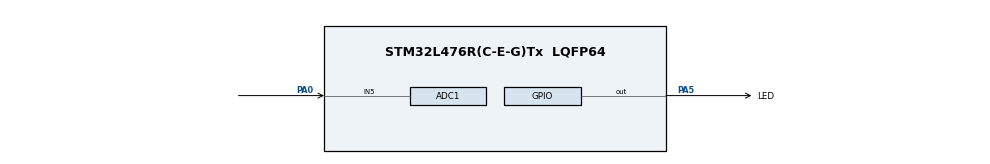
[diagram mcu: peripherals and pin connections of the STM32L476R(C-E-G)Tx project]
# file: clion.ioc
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ADC1.Channel-0\#ChannelRegularConversion=ADC_CHANNEL_5
ADC1.ClockPrescaler=ADC_CLOCK_SYNC_PCLK_DIV4
ADC1.NbrOfConversionFlag=1
ADC1.OffsetNumber-0\#ChannelRegularConversion=ADC_OFFSET_NONE
ADC1.Rank-0\#ChannelRegularConversion=1
ADC1.SamplingTime-0\#ChannelRegularConversion=ADC_SAMPLETIME_92CYCLES_5
ADC1.master=1
Mcu.Family=STM32L4
Mcu.Name=STM32L476R(C-E-G)Tx
Mcu.Package=LQFP64
NVIC.ADC1_2_IRQn=true\:0\:0\:false\:false\:true\:true\:true
NVIC.PriorityGroup=NVIC_PRIORITYGROUP_4
PA0.Signal=ADCx_IN5
PA5.GPIO_Label=LED
PA5.Signal=GPIO_Output
ProjectManager.HeapSize=0x200
ProjectManager.StackSize=0x400
ProjectManager.TargetToolchain=SW4STM32
RCC.ADCFreq_Value=32000000
RCC.HSE_VALUE=8000000
RCC.HSI_VALUE=16000000
RCC.LSE_VALUE=32768
RCC.MSI_VALUE=4000000
RCC.PLLSAI1N=16
RCC.USBFreq_Value=32000000
RCC.VCOOutputFreq_Value=32000000
SH.ADCx_IN5.0=ADC1_IN5,IN5-Single-Ended
board=custom

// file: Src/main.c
/* USER CODE BEGIN Header */
/**
 ******************************************************************************
 * @file           : main.c
 * @brief          : Main program body
 ******************************************************************************
 * @attention
 *
 * <h2><center>&copy; Copyright (c) 2019 STMicroelectronics.
 * All rights reserved.</center></h2>
 *
 * This software component is licensed by ST under BSD 3-Clause license,
 * the "License"; You may not use this file except in compliance with the
 * License. You may obtain a copy of the License at:
 *                        opensource.org/licenses/BSD-3-Clause
 *
 ******************************************************************************
 */
/* USER CODE END Header */

#include "main.h"

ADC_HandleTypeDef hadc1;

void SystemClock_Config(void);
static void MX_GPIO_Init(void);
static void MX_ADC1_Init(void);

/* USER CODE BEGIN 0 */
uint32_t value;

void HAL_ADC_ConvCpltCallback(ADC_HandleTypeDef *hadc1) {
    value = HAL_ADC_GetValue(hadc1);
    HAL_ADC_Start_IT(hadc1); // Re-Start ADC1 under Interrupt
    // this is necessary because we don'use
    // the Continuous Conversion Mode
}
/* USER CODE END 0 */

int main(void)
{

  /* MCU Configuration--------------------------------------------------------*/

  /* Reset of all peripherals, Initializes the Flash interface and the Systick. */
  HAL_Init();

  /* Configure the system clock */
  SystemClock_Config();

  /* Initialize all configured peripherals */
  MX_GPIO_Init();
  MX_ADC1_Init();
  /* USER CODE BEGIN 2 */
    HAL_ADC_Start_IT(&hadc1);  // start ADC in interrupt mode
  /* USER CODE END 2 */

  /* Infinite loop */
  /* USER CODE BEGIN WHILE */
    while (1) {
        HAL_GPIO_TogglePin(LED_GPIO_Port, LED_Pin);
        HAL_Delay(value / 10 + 20);
//        TODO implement storage to flash
        if (value > 9999) {
            break;
        }
    /* USER CODE END WHILE */

    }
}

void SystemClock_Config(void)
{
  RCC_OscInitTypeDef RCC_OscInitStruct = {0};
  RCC_ClkInitTypeDef RCC_ClkInitStruct = {0};

  /** Initializes the CPU, AHB and APB busses clocks
  */
  RCC_OscInitStruct.OscillatorType = RCC_OSCILLATORTYPE_MSI;
  RCC_OscInitStruct.MSIState = RCC_MSI_ON;
  RCC_OscInitStruct.MSICalibrationValue = 0;
  RCC_OscInitStruct.MSIClockRange = RCC_MSIRANGE_6;
  RCC_OscInitStruct.PLL.PLLState = RCC_PLL_NONE;
  if (HAL_RCC_OscConfig(&RCC_OscInitStruct) != HAL_OK)
  {
    Error_Handler();
  }
  /** Initializes the CPU, AHB and APB busses clocks
  */
  RCC_ClkInitStruct.ClockType = RCC_CLOCKTYPE_HCLK|RCC_CLOCKTYPE_SYSCLK
                              |RCC_CLOCKTYPE_PCLK1|RCC_CLOCKTYPE_PCLK2;
  RCC_ClkInitStruct.SYSCLKSource = RCC_SYSCLKSOURCE_MSI;
  RCC_ClkInitStruct.AHBCLKDivider = RCC_SYSCLK_DIV1;
  RCC_ClkInitStruct.APB1CLKDivider = RCC_HCLK_DIV1;
  RCC_ClkInitStruct.APB2CLKDivider = RCC_HCLK_DIV1;

  if (HAL_RCC_ClockConfig(&RCC_ClkInitStruct, FLASH_LATENCY_0) != HAL_OK)
  {
    Error_Handler();
  }
  /** Configure the main internal regulator output voltage
  */
  if (HAL_PWREx_ControlVoltageScaling(PWR_REGULATOR_VOLTAGE_SCALE1) != HAL_OK)
  {
    Error_Handler();
  }
}

static void MX_ADC1_Init(void)
{

  ADC_MultiModeTypeDef multimode = {0};
  ADC_ChannelConfTypeDef sConfig = {0};

  /** Common config
  */
  hadc1.Instance = ADC1;
  hadc1.Init.ClockPrescaler = ADC_CLOCK_SYNC_PCLK_DIV4;
  hadc1.Init.Resolution = ADC_RESOLUTION_12B;
  hadc1.Init.DataAlign = ADC_DATAALIGN_RIGHT;
  hadc1.Init.ScanConvMode = ADC_SCAN_DISABLE;
  hadc1.Init.EOCSelection = ADC_EOC_SINGLE_CONV;
  hadc1.Init.LowPowerAutoWait = DISABLE;
  hadc1.Init.ContinuousConvMode = DISABLE;
  hadc1.Init.NbrOfConversion = 1;
  hadc1.Init.DiscontinuousConvMode = DISABLE;
  hadc1.Init.ExternalTrigConv = ADC_SOFTWARE_START;
  hadc1.Init.ExternalTrigConvEdge = ADC_EXTERNALTRIGCONVEDGE_NONE;
  hadc1.Init.DMAContinuousRequests = DISABLE;
  hadc1.Init.Overrun = ADC_OVR_DATA_PRESERVED;
  hadc1.Init.OversamplingMode = DISABLE;
  if (HAL_ADC_Init(&hadc1) != HAL_OK)
  {
    Error_Handler();
  }
  /** Configure the ADC multi-mode
  */
  multimode.Mode = ADC_MODE_INDEPENDENT;
  if (HAL_ADCEx_MultiModeConfigChannel(&hadc1, &multimode) != HAL_OK)
  {
    Error_Handler();
  }
  /** Configure Regular Channel
  */
  sConfig.Channel = ADC_CHANNEL_5;
  sConfig.Rank = ADC_REGULAR_RANK_1;
  sConfig.SamplingTime = ADC_SAMPLETIME_92CYCLES_5;
  sConfig.SingleDiff = ADC_SINGLE_ENDED;
  sConfig.OffsetNumber = ADC_OFFSET_NONE;
  sConfig.Offset = 0;
  if (HAL_ADC_ConfigChannel(&hadc1, &sConfig) != HAL_OK)
  {
    Error_Handler();
  }

}

static void MX_GPIO_Init(void)
{
  GPIO_InitTypeDef GPIO_InitStruct = {0};

  /* GPIO Ports Clock Enable */
  __HAL_RCC_GPIOA_CLK_ENABLE();

  /*Configure GPIO pin Output Level */
  HAL_GPIO_WritePin(LED_GPIO_Port, LED_Pin, GPIO_PIN_RESET);

  /*Configure GPIO pin : LED_Pin */
  GPIO_InitStruct.Pin = LED_Pin;
  GPIO_InitStruct.Mode = GPIO_MODE_OUTPUT_PP;
  GPIO_InitStruct.Pull = GPIO_NOPULL;
  GPIO_InitStruct.Speed = GPIO_SPEED_FREQ_LOW;
  HAL_GPIO_Init(LED_GPIO_Port, &GPIO_InitStruct);

}

void Error_Handler(void)
{
}

/************************ (C) COPYRIGHT STMicroelectronics *****END OF FILE****/
